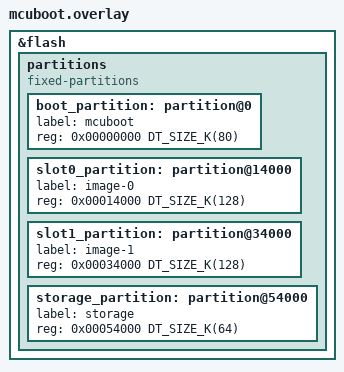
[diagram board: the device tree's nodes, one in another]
/delete-node/ &slot0_partition;
/delete-node/ &slot1_partition;

&flash {
	partitions {
		compatible = "fixed-partitions";
		#address-cells = <1>;
		#size-cells = <1>;

		boot_partition: partition@0 {
			label = "mcuboot";
			reg = <0x00000000 DT_SIZE_K(80)>;
		};
		slot0_partition: partition@14000 {
			label = "image-0";
			reg = <0x00014000 DT_SIZE_K(128)>;
		};
		slot1_partition: partition@34000 {
			label = "image-1";
			reg = <0x00034000 DT_SIZE_K(128)>;
		};
		storage_partition: partition@54000 {
			label = "storage";
			reg = <0x00054000 DT_SIZE_K(64)>;
		};
	};
};

